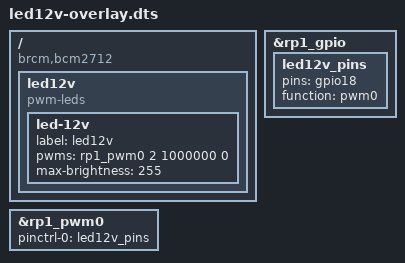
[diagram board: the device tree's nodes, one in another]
/dts-v1/;
/plugin/;

/ {
	compatible = "brcm,bcm2712";

	fragment@0 {
		target = <&rp1_gpio>;
		__overlay__ {
			led12v_pins: led12v_pins {
				pins = "gpio18";
				function = "pwm0";
			};
		};
	};

	fragment@1 {
		target = <&rp1_pwm0>;
		__overlay__ {
			pinctrl-names = "default";
			pinctrl-0 = <&led12v_pins>;
			status = "okay";
		};
	};

	fragment@2 {
		target-path = "/";
		__overlay__ {
			led12v {
				compatible = "pwm-leds";

				led-12v {
					label = "led12v";
					pwms = <&rp1_pwm0 2 1000000 0>;
					max-brightness = <255>;
				};
			};
		};
	};
};
